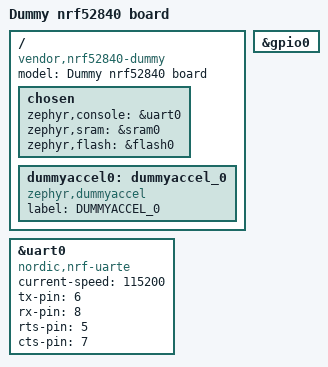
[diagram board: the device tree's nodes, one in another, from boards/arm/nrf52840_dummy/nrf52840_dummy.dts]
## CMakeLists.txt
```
cmake_minimum_required(VERSION 3.13.1)

set(OVERLAY_CONFIG debug.conf rtt.conf)
list(APPEND BOARD_ROOT ${CMAKE_CURRENT_SOURCE_DIR})
list(APPEND DTS_ROOT ${CMAKE_CURRENT_SOURCE_DIR})
set(BOARD nrf52840_dummy)

find_package(Zephyr REQUIRED HINTS $ENV{ZEPHYR_BASE})
add_subdirectory(drivers)

project(zephyr_testrepo LANGUAGES C VERSION 0.0.1)

configure_file(app_version.h.in ${CMAKE_BINARY_DIR}/app/include/app_version.h)
target_include_directories(app PRIVATE ${CMAKE_BINARY_DIR}/app/include src)

target_sources(app PRIVATE src/main.c)
```

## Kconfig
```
# Copyright (c) 2021 Nordic Semiconductor ASA
# SPDX-License-Identifier: Apache-2.0
#
# This file is the application Kconfig entry point. All application Kconfig
# options can be defined here or included via other application Kconfig files.
# You can browse these options using the west targets menuconfig (terminal) or
# guiconfig (GUI).

menu "Zephyr"
source "Kconfig.zephyr"
endmenu

module = APP
module-str = APP
source "subsys/logging/Kconfig.template.log_config"

rsource "drivers/Kconfig"
```

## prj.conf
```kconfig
CONFIG_SENSOR=y
CONFIG_DUMMYACCEL=y
```

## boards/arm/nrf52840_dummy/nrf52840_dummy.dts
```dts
/*
 * Copyright (c) 2021 Nordic Semiconductor ASA
 * SPDX-License-Identifier: Apache-2.0
 */

/dts-v1/;
#include <nordic/nrf52840_qiaa.dtsi>

/ {
	model = "Dummy nrf52840 board";
	compatible = "vendor,nrf52840-dummy";

	chosen {
		zephyr,console = &uart0;
		zephyr,sram = &sram0;
		zephyr,flash = &flash0;
	};

	dummyaccel0: dummyaccel_0 {
		compatible = "zephyr,dummyaccel";
		label = "DUMMYACCEL_0";
        status = "okay";
	};
};

&gpio0 {
	status = "okay";
};

&uart0 {
	compatible = "nordic,nrf-uarte";
	status = "okay";

	current-speed = <115200>;
	tx-pin = <6>;
	rx-pin = <8>;
	rts-pin = <5>;
	cts-pin = <7>;
};
```

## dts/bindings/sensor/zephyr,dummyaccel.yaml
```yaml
# Copyright (c) 2021 Nordic Semiconductor ASA
# SPDX-License-Identifier: Apache-2.0

description: |
  A dummy accelerometer sensor

compatible: "zephyr,dummyaccel"
```

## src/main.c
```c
#include <zephyr.h>
#include <drivers/sensor.h>

#include "app_version.h"

#include <logging/log.h>

LOG_MODULE_REGISTER(main, CONFIG_APP_LOG_LEVEL);

void main(void)
{
	int ret;

	const struct device *dummy_accel;
	dummy_accel = DEVICE_DT_GET(DT_NODELABEL(dummyaccel0));
	
	if (!device_is_ready(dummy_accel)) {
		LOG_ERR("Sensor not ready");
		return;
	}

	printk("Zephyr Example Application %s\n", APP_VERSION_STR);

	while (1) {

		printk("hi\n");

		k_sleep(K_MSEC(1000));
	}
}
```
